VERSION ""

NS_ :

BS_:
BU_: telemetry_board test_device
BO_ 2147483648 bat_data: 8 test_device
   SG_ bat_vsig : 7|32@0- (1,0) [0|300] "volts" telemetry_board
   SG_ bat_csig : 39|32@0- (1,0) [0|200] "amps" telemetry_board

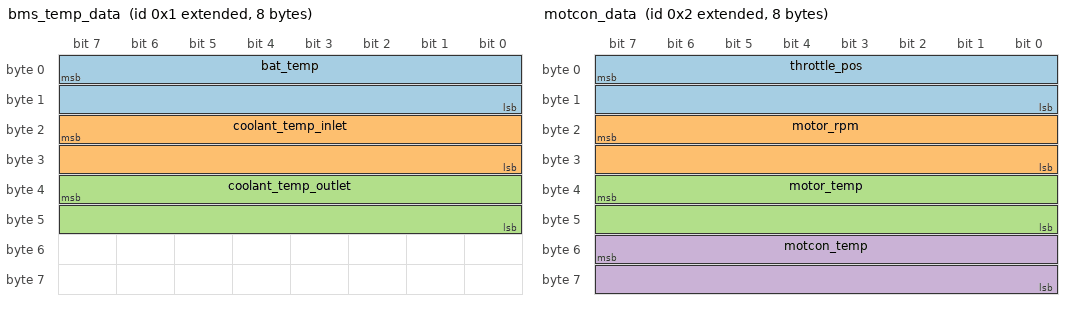
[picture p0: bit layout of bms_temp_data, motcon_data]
BO_ 2147483649 bms_temp_data: 8 test_device
   SG_ bat_temp : 7|16@0+ (0.1,0) [0|100] "Celsius" telemetry_board
   SG_ coolant_temp_inlet : 23|16@0+ (0.1,0) [0|100] "Celsius" telemetry_board
   SG_ coolant_temp_outlet : 39|16@0+ (0.1,0) [0|100] "Celsius" telemetry_board

BO_ 2147483650 motcon_data: 8 test_device
   SG_ throttle_pos : 7|16@0+ (0.1,0) [0|100] "" telemetry_board
   SG_ motor_rpm : 23|16@0+ (1,0) [0|300000] "RPM" telemetry_board
   SG_ motor_temp : 39|16@0+ (0.1,0) [0|100] "Celsius" telemetry_board
   SG_ motcon_temp : 55|16@0+ (0.1,0) [0|100] "Celsius" telemetry_board

BA_DEF_ BO_ "GenMsgBackgroundColor" STRING ;
BA_DEF_ BO_ "GenMsgForegroundColor" STRING ;
BA_DEF_ BO_ "filterlabeling" INT 0 0;
BA_DEF_ BO_ "GenMsgCycleTime" INT 0 65535;
BA_DEF_DEF_ "GenMsgBackgroundColor" "#ffffff";
BA_DEF_DEF_ "GenMsgForegroundColor" "#000000";
BA_DEF_DEF_ "filterlabeling" 1;

BA_ "GenMsgCycleTime" BO_ 2147483648 100;
BA_ "GenMsgCycleTime" BO_ 2147483649 700;
BA_ "GenMsgCycleTime" BO_ 2147483650 500;
